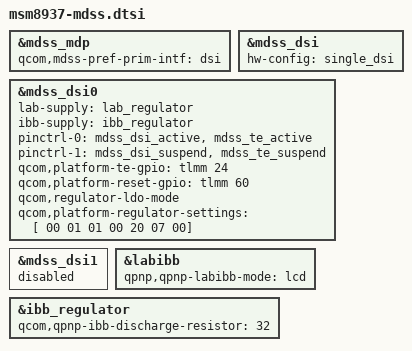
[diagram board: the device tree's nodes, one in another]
&mdss_mdp {
	qcom,mdss-pref-prim-intf = "dsi";
};

&mdss_dsi {
	hw-config = "single_dsi";
};

&mdss_dsi0 {
	lab-supply = <&lab_regulator>;
	ibb-supply = <&ibb_regulator>;

	pinctrl-names = "mdss_default", "mdss_sleep";
	pinctrl-0 = <&mdss_dsi_active &mdss_te_active>;
	pinctrl-1 = <&mdss_dsi_suspend &mdss_te_suspend>;

	qcom,platform-te-gpio = <&tlmm 24 0>;
	qcom,platform-reset-gpio = <&tlmm 60 0>;

	qcom,regulator-ldo-mode;
	qcom,platform-regulator-settings = [ 00 01 01 00 20 07 00];

};

&mdss_dsi1 {
	status = "disabled";
};

&labibb {
	status = "ok";
	qpnp,qpnp-labibb-mode = "lcd";
};

&ibb_regulator {
	qcom,qpnp-ibb-discharge-resistor = <32>;
};
